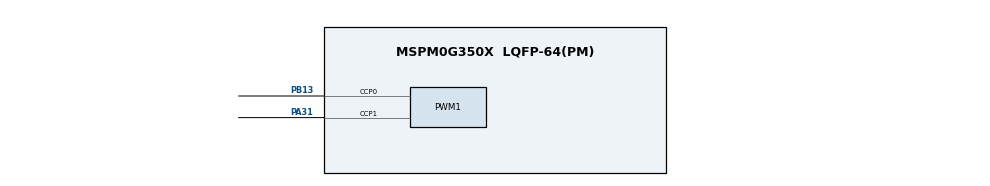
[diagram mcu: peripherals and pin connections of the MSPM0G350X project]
/**
 * @cliArgs --device "MSPM0G350X" --part "Default" --package "LQFP-64(PM)" --product "mspm0_sdk@2.02.00.05"
 * @versions {"tool":"1.21.0+3721"}
 */

/**
 * Import the modules used in this configuration.
 */
const GPIO   = scripting.addModule("/ti/driverlib/GPIO", {}, false);
const GPIO1  = GPIO.addInstance();
const PWM    = scripting.addModule("/ti/driverlib/PWM", {}, false);
const PWM1   = PWM.addInstance();
const SYSCTL = scripting.addModule("/ti/driverlib/SYSCTL");

/**
 * Write custom configuration values to the imported modules.
 */
GPIO1.$name                              = "GPIO_GRP_0";
GPIO1.associatedPins.create(2);
GPIO1.associatedPins[0].$name            = "k1";
GPIO1.associatedPins[0].direction        = "INPUT";
GPIO1.associatedPins[0].assignedPin      = "18";
GPIO1.associatedPins[0].assignedPort     = "PORTA";
GPIO1.associatedPins[1].$name            = "k2";
GPIO1.associatedPins[1].direction        = "INPUT";
GPIO1.associatedPins[1].assignedPort     = "PORTB";
GPIO1.associatedPins[1].assignedPin      = "21";
GPIO1.associatedPins[1].internalResistor = "PULL_UP";
GPIO1.associatedPins[1].invert           = "ENABLE";

const Board = scripting.addModule("/ti/driverlib/Board", {}, false);

PWM1.$name                      = "PWM_0";
PWM1.timerCount                 = 200000;
PWM1.peripheral.$assign         = "TIMG12";
PWM1.peripheral.ccp0Pin.$assign = "PB13";
PWM1.peripheral.ccp1Pin.$assign = "PA31";
PWM1.PWM_CHANNEL_0.$name        = "ti_driverlib_pwm_PWMTimerCC0";
PWM1.PWM_CHANNEL_1.$name        = "ti_driverlib_pwm_PWMTimerCC1";
PWM1.ccp0PinConfig.$name        = "ti_driverlib_gpio_GPIOPinGeneric0";
PWM1.ccp1PinConfig.$name        = "ti_driverlib_gpio_GPIOPinGeneric1";

SYSCTL.forceDefaultClkConfig = true;

/**
 * Pinmux solution for unlocked pins/peripherals. This ensures that minor changes to the automatic solver in a future
 * version of the tool will not impact the pinmux you originally saw.  These lines can be completely deleted in order to
 * re-solve from scratch.
 */
GPIO1.associatedPins[0].pin.$suggestSolution = "PA18";
GPIO1.associatedPins[1].pin.$suggestSolution = "PB21";
Board.peripheral.$suggestSolution            = "DEBUGSS";
Board.peripheral.swclkPin.$suggestSolution   = "PA20";
Board.peripheral.swdioPin.$suggestSolution   = "PA19";
SYSCTL.peripheral.$suggestSolution           = "SYSCTL";
